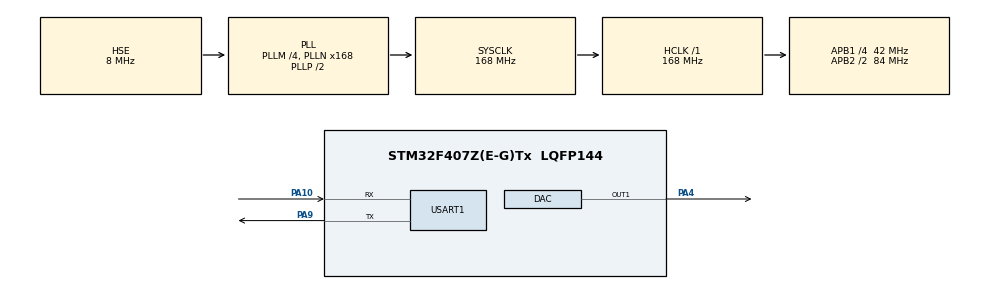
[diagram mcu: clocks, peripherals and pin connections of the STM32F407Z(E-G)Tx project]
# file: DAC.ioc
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DAC.DAC_Trigger=DAC_TRIGGER_T2_TRGO
DAC.WaveGeneration=DISABLE
Dma.DAC1.0.Direction=DMA_MEMORY_TO_PERIPH
Dma.DAC1.0.FIFOMode=DMA_FIFOMODE_DISABLE
Dma.DAC1.0.Instance=DMA1_Stream5
Dma.DAC1.0.MemDataAlignment=DMA_MDATAALIGN_HALFWORD
Dma.DAC1.0.MemInc=DMA_MINC_ENABLE
Dma.DAC1.0.Mode=DMA_CIRCULAR
Dma.DAC1.0.PeriphDataAlignment=DMA_PDATAALIGN_HALFWORD
Dma.DAC1.0.PeriphInc=DMA_PINC_DISABLE
Dma.DAC1.0.Priority=DMA_PRIORITY_LOW
Dma.Request0=DAC1
FREERTOS.Tasks01=MainTask,24,256,StartMainTask,Default,NULL,Dynamic,NULL,NULL
Mcu.Family=STM32F4
Mcu.Name=STM32F407Z(E-G)Tx
Mcu.Package=LQFP144
NVIC.DMA1_Stream5_IRQn=true\:5\:0\:false\:false\:true\:true\:false\:true
NVIC.PriorityGroup=NVIC_PRIORITYGROUP_4
NVIC.TIM8_TRG_COM_TIM14_IRQn=true\:0\:0\:false\:false\:true\:false\:false\:true
NVIC.TimeBase=TIM8_TRG_COM_TIM14_IRQn
NVIC.TimeBaseIP=TIM14
PA10.Mode=Asynchronous
PA10.Signal=USART1_RX
PA13.Mode=Serial_Wire
PA13.Signal=SYS_JTMS-SWDIO
PA14.Mode=Serial_Wire
PA14.Signal=SYS_JTCK-SWCLK
PA4.Signal=COMP_DAC1_group
PA9.Mode=Asynchronous
PA9.Signal=USART1_TX
PH0-OSC_IN.Mode=HSE-External-Oscillator
PH0-OSC_IN.Signal=RCC_OSC_IN
PH1-OSC_OUT.Mode=HSE-External-Oscillator
PH1-OSC_OUT.Signal=RCC_OSC_OUT
ProjectManager.HeapSize=0x200
ProjectManager.StackSize=0x400
ProjectManager.TargetToolchain=STM32CubeIDE
RCC.48MHZClocksFreq_Value=84000000
RCC.AHBFreq_Value=168000000
RCC.APB1CLKDivider=RCC_HCLK_DIV4
RCC.APB1Freq_Value=42000000
RCC.APB1TimFreq_Value=84000000
RCC.APB2CLKDivider=RCC_HCLK_DIV2
RCC.APB2Freq_Value=84000000
RCC.APB2TimFreq_Value=168000000
RCC.CortexFreq_Value=168000000
RCC.HCLKFreq_Value=168000000
RCC.HSE_VALUE=8000000
RCC.HSI_VALUE=16000000
RCC.LSE_VALUE=32768
RCC.PLLM=4
RCC.PLLN=168
RCC.PLLSourceVirtual=RCC_PLLSOURCE_HSE
RCC.SYSCLKFreq_VALUE=168000000
RCC.SYSCLKSource=RCC_SYSCLKSOURCE_PLLCLK
RCC.VCOOutputFreq_Value=336000000
SH.COMP_DAC1_group.0=DAC_OUT1,DAC_OUT1
TIM2.Period=0
TIM2.Prescaler=9
TIM2.TIM_MasterOutputTrigger=TIM_TRGO_UPDATE
USART1.VirtualMode=VM_ASYNC
VP_FREERTOS_VS_CMSIS_V2.Mode=CMSIS_V2
VP_SYS_VS_tim14.Mode=TIM14
VP_TIM2_VS_ClockSourceINT.Mode=Internal
board=custom

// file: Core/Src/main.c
/* USER CODE BEGIN Header */
/**
  ******************************************************************************
  * @file           : main.c
  * @brief          : Main program body
  ******************************************************************************
  * @attention
  *
  * <h2><center>&copy; Copyright (c) 2020 STMicroelectronics.
  * All rights reserved.</center></h2>
  *
  * This software component is licensed by ST under Ultimate Liberty license
  * SLA0044, the "License"; You may not use this file except in compliance with
  * the License. You may obtain a copy of the License at:
  *                             www.st.com/SLA0044
  *
  ******************************************************************************
  */
/* USER CODE END Header */
#include "main.h"
#include "cmsis_os.h"
#include "dac.h"
#include "dma.h"
#include "tim.h"
#include "usart.h"
#include "gpio.h"

void SystemClock_Config(void);
void MX_FREERTOS_Init(void);

int main(void)
{

  /* MCU Configuration--------------------------------------------------------*/

  /* Reset of all peripherals, Initializes the Flash interface and the Systick. */
  HAL_Init();

  /* Configure the system clock */
  SystemClock_Config();

  /* Initialize all configured peripherals */
  MX_GPIO_Init();
  MX_DMA_Init();
  MX_USART1_UART_Init();
  MX_DAC_Init();
  MX_TIM2_Init();

  /* Init scheduler */
  osKernelInitialize();  /* Call init function for freertos objects (in freertos.c) */
  MX_FREERTOS_Init();
  /* Start scheduler */
  osKernelStart();

  /* We should never get here as control is now taken by the scheduler */
  /* Infinite loop */
  while (1)
  {

  }
}

void SystemClock_Config(void)
{
  RCC_OscInitTypeDef RCC_OscInitStruct = {0};
  RCC_ClkInitTypeDef RCC_ClkInitStruct = {0};

  /** Configure the main internal regulator output voltage
  */
  __HAL_RCC_PWR_CLK_ENABLE();
  __HAL_PWR_VOLTAGESCALING_CONFIG(PWR_REGULATOR_VOLTAGE_SCALE1);
  /** Initializes the RCC Oscillators according to the specified parameters
  * in the RCC_OscInitTypeDef structure.
  */
  RCC_OscInitStruct.OscillatorType = RCC_OSCILLATORTYPE_HSE;
  RCC_OscInitStruct.HSEState = RCC_HSE_ON;
  RCC_OscInitStruct.PLL.PLLState = RCC_PLL_ON;
  RCC_OscInitStruct.PLL.PLLSource = RCC_PLLSOURCE_HSE;
  RCC_OscInitStruct.PLL.PLLM = 4;
  RCC_OscInitStruct.PLL.PLLN = 168;
  RCC_OscInitStruct.PLL.PLLP = RCC_PLLP_DIV2;
  RCC_OscInitStruct.PLL.PLLQ = 4;
  if (HAL_RCC_OscConfig(&RCC_OscInitStruct) != HAL_OK)
  {
    Error_Handler();
  }
  /** Initializes the CPU, AHB and APB buses clocks
  */
  RCC_ClkInitStruct.ClockType = RCC_CLOCKTYPE_HCLK|RCC_CLOCKTYPE_SYSCLK
                              |RCC_CLOCKTYPE_PCLK1|RCC_CLOCKTYPE_PCLK2;
  RCC_ClkInitStruct.SYSCLKSource = RCC_SYSCLKSOURCE_PLLCLK;
  RCC_ClkInitStruct.AHBCLKDivider = RCC_SYSCLK_DIV1;
  RCC_ClkInitStruct.APB1CLKDivider = RCC_HCLK_DIV4;
  RCC_ClkInitStruct.APB2CLKDivider = RCC_HCLK_DIV2;

  if (HAL_RCC_ClockConfig(&RCC_ClkInitStruct, FLASH_LATENCY_5) != HAL_OK)
  {
    Error_Handler();
  }
}

 /**
  * @brief  Period elapsed callback in non blocking mode
  * @note   This function is called  when TIM14 interrupt took place, inside
  * HAL_TIM_IRQHandler(). It makes a direct call to HAL_IncTick() to increment
  * a global variable "uwTick" used as application time base.
  * @param  htim : TIM handle
  * @retval None
  */
void HAL_TIM_PeriodElapsedCallback(TIM_HandleTypeDef *htim)
{
  if (htim->Instance == TIM14) {
    HAL_IncTick();
  }
}

void Error_Handler(void)
{
  __disable_irq();
  while (1)
  {
  }
}

/************************ (C) COPYRIGHT STMicroelectronics *****END OF FILE****/

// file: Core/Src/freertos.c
/* USER CODE BEGIN Header */
/**
  ******************************************************************************
  * File Name          : freertos.c
  * Description        : Code for freertos applications
  ******************************************************************************
  * @attention
  *
  * <h2><center>&copy; Copyright (c) 2020 STMicroelectronics.
  * All rights reserved.</center></h2>
  *
  * This software component is licensed by ST under Ultimate Liberty license
  * SLA0044, the "License"; You may not use this file except in compliance with
  * the License. You may obtain a copy of the License at:
  *                             www.st.com/SLA0044
  *
  ******************************************************************************
  */
/* USER CODE END Header */

#include "FreeRTOS.h"
#include "task.h"
#include "main.h"
#include "cmsis_os.h"

/* USER CODE BEGIN Includes */
#include <math.h>
#include <stdio.h>
#include "tim.h"
#include "dac.h"
/* USER CODE END Includes */

/* USER CODE BEGIN PD */
#define PI 3.1415926
/* USER CODE END PD */

/* Definitions for MainTask */
osThreadId_t MainTaskHandle;
const osThreadAttr_t MainTask_attributes = {
  .name = "MainTask",
  .priority = (osPriority_t) osPriorityNormal,
  .stack_size = 256 * 4
};

/* USER CODE BEGIN FunctionPrototypes */
void SquareWave(uint16_t *D, float Um, uint16_t cycle);

void TriangleWave(uint16_t *D, float Um, uint16_t cycle);

void SineWave(uint16_t *D, float Um, uint16_t cycle);

void SpecialWave(uint16_t *D);
/* USER CODE END FunctionPrototypes */

void StartMainTask(void *argument);

void MX_FREERTOS_Init(void); /* (MISRA C 2004 rule 8.1) */

void MX_FREERTOS_Init(void) {

  /* Create the thread(s) */
  /* creation of MainTask */
  MainTaskHandle = osThreadNew(StartMainTask, NULL, &MainTask_attributes);

}

void StartMainTask(void *argument)
{
  /* USER CODE BEGIN StartMainTask */
        uint16_t SquareWave_Value[168];
        uint16_t TriangleWave_Value[168];
        uint16_t SineWave_Value[168];
        uint16_t SpecialWave_Value[168];

        SquareWave(SquareWave_Value,3,168);
        TriangleWave(TriangleWave_Value,1.5,168);
        SineWave(SineWave_Value,1.5,168);

        HAL_TIM_Base_Start(&htim2);
        HAL_DAC_Start_DMA(&hdac, DAC_CHANNEL_1, (uint32_t *)SquareWave_Value, 168, DAC_ALIGN_12B_R);
        HAL_DAC_Stop_DMA(&hdac, DAC_CHANNEL_1);
    /* Infinite loop */
    for (;;) {
        osDelay(1);
    }
  /* USER CODE END StartMainTask */
}

/* USER CODE BEGIN Application */
/********方波输出表***********/
//cycle :波形表的位数 (0~256)
//Um        :输出电压的峰值(0~3.3)
/*******************************/
void SquareWave(uint16_t *D, float Um, uint16_t cycle) {
    for (int i = 0; i < cycle; i++) {
        if (i < cycle / 2)
            D[i] = (uint16_t) (Um * 4095 / 3.3);
        else
            D[i] = (uint16_t) (0);
    }
}

/********三角波输出表***********/
//cycle :波形表的位数 (0~256)
//Um        :输出电压的峰值(0~1.5)
/*******************************/
void TriangleWave(uint16_t *D, float Um, uint16_t cycle) {
    for (int i = 0; i < cycle; i++) {
        if (i < 23)
            D[i] = (uint16_t) ((Um + i * Um / 24) * 4095 / 3.3);
        else if (i < 72)
            D[i] = (uint16_t) ((2 * Um - (i - 23) * Um / 24) * 4095 / 3.3);
        else
            D[i] = (uint16_t) (((i - 71) * Um / 24) * 4095 / 3.3);
    }
}

/********正弦波输出表***********/
//cycle :波形表的位数 (0~256)
//Um        :输出电压的峰值(0~1.5)
/*******************************/
void SineWave(uint16_t *D, float Um, uint16_t cycle) {
    for (int i = 0; i < cycle; i++) {
        D[i] = (uint16_t) ((Um * sin((1.0 * i / (cycle - 1)) * 2 * PI) + Um) * 4095 / 3.3);
    }
}

//生成特殊波形的数据表
void SpecialWave(uint16_t *D) {
    for (int i = 0; i < 300; i++) {
        if (i < 55)
            D[i] = (uint16_t) ((2 - i / 54.0) * 4095 / 3.3);
        else if (i < 110)
            D[i] = (uint16_t) ((1 + (i - 55) / 54.0) * 4095 / 3.3);
        else if (i < 190)
            D[i] = (uint16_t) (0);
        else if (i < 245)
            D[i] = (uint16_t) (2 * sin((i - 190) / 54.0 * PI / 2) * 4095 / 3.3);
        else if (i < 300)
            D[i] = (uint16_t) ((2 - (i - 245) / 54.0 * 2) * 4095 / 3.3);
    }
}
/* USER CODE END Application */

/************************ (C) COPYRIGHT STMicroelectronics *****END OF FILE****/
